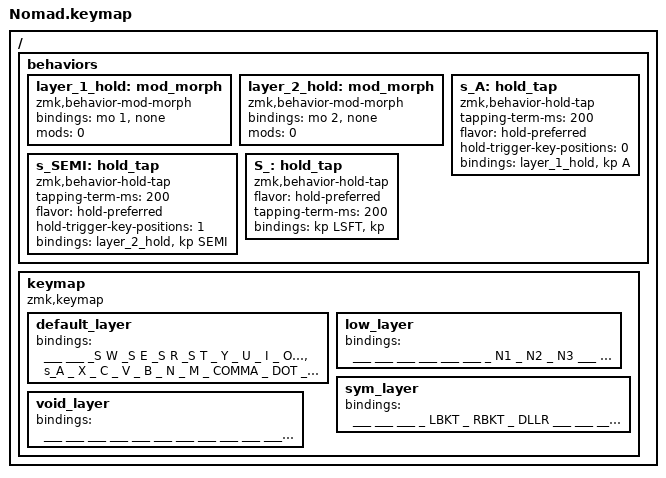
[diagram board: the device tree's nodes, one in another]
#include <behaviors.dtsi>
#include <dt-bindings/zmk/keys.h>
#include <dt-bindings/zmk/bt.h>

//custom includes
#include "include/positions.h"
#include "include/settings.dtsi"
#include "include/homerowmods.dtsi"

#define ___ &trans
#define _ &kp
#define _l &mo
#define _BOOT &bootloader
#define _CLR &bt BT_CLR
#define XXX &none

#define LOW 1
#define SYM 2

#define S_A &hm_shift_l LSHFT A
#define S_SEMI &hm_shift_r SEMI

/ {
  behaviors {
    layer_1_hold: mod_morph {
      compatible = "zmk,behavior-mod-morph";
      bindings = <&mo 1>, <&none>;
      mods = <0>;
    };

    layer_2_hold: mod_morph {
      compatible = "zmk,behavior-mod-morph";
      bindings = <&mo 2>, <&none>;
      mods = <0>;
    };

    s_A: hold_tap {
      compatible = "zmk,behavior-hold-tap";
      tapping-term-ms = <200>;
      flavor = "hold-preferred";
      hold-trigger-key-positions = <0>;
      bindings = <&layer_1_hold>, <&kp A>;
    };

    s_SEMI: hold_tap {
      compatible = "zmk,behavior-hold-tap";
      tapping-term-ms = <200>;
      flavor = "hold-preferred";
      hold-trigger-key-positions = <1>;
      bindings = <&layer_2_hold>, <&kp SEMI>;
    };
  };

  behaviors {
    S_: hold_tap {
      compatible = "zmk,behavior-hold-tap";
      #binding-cells = <1>;
      flavor = "hold-preferred";
      tapping-term-ms = <200>;
      bindings = <&kp LSFT>, <&kp>;
    };
  };

  keymap {
    compatible = "zmk,keymap";

    default_layer {
      bindings = <
        //                   ╭───────┬───────┬───────┬───────╮ ╭───────┬───────┬───────┬───────╮               
                ___     ___   _ W     _ E     _ R     _ T       _ Y     _ U     _ I     _ O       ___     ___  
        //   ╭───-───┬───-───┼───-───┼───-───┼───-───┼───-───┤ ├───-───┬───-───┼───-───┼───-───┼───-───┼───-───╮
              _ TAB   _ Q     _ S     _ D     _ F     _ G       _ H     _ J     _ K     _ L     _ P       ___  
        //   ├───-───┼───-───┼───-───┼───-───┼───-───┼───-───┤ ├───-───┼───-───┼───-───┼───-───┼───-───┼───-───┤
              _ CAPS  &s_A    _ X     _ C     _ V     _ B       _ N     _ M     _ COMMA _ DOT   _ SEMI  _ SQT  
        //   ├───-───┼───-───┼───-───┼───-───┼───-───┼───-───┤ ├───-───┼───-───┼───-───┼───-───┼───-───┼───-───┤
              _ LSHFT _ Z     _ LGUI  _l LOW  _ RET   _ SPACE   _ BSPC  _ RCTRL _l SYM  _ RALT  _ N8    _ RSHFT
        //   ╰───-───┴───-───┴───-───┴───-───┴───-───┴───-───╯ ╰───-───┴───-───┴───-───┴───-───┴───-───┴───-───╯
      >;
    };

    default_layer {
      bindings = <
        //                   ╭───────┬───────┬───────┬───────╮ ╭───────┬───────┬───────┬───────╮               
                ___     ___   _ W     _ E     _ R     _ T       _S Y    _S U    _S I    _S O      ___     ___  
        //   ╭───-───┬───-───┼───-───┼───-───┼───-───┼───-───┤ ├───-───┬───-───┼───-───┼───-───┼───-───┼───-───╮
              _ TAB   _ Q     _ S     _ D     _ F     _ G       _S H    _S J    _S K    _S L    _S P      ___  
        //   ├───-───┼───-───┼───-───┼───-───┼───-───┼───-───┤ ├───-───┼───-───┼───-───┼───-───┼───-───┼───-───┤
              _ CAPS  &s_A    _ X     _ C     _ V     _ B       _S N    _S M    _S COMMA _ DOT   _S SEMI _S SQT 
        //   ├───-───┼───-───┼───-───┼───-───┼───-───┼───-───┤ ├───-───┼───-───┼───-───┼───-───┼───-───┼───-───┤
              _ LSHFT _ Z     _ LGUI  _l LOW  _ RET   _ SPACE   _ BSPC  _ RCTRL _l SYM  _ RALT  _ N8    _ RSHFT
        //   ╰───-───┴───-───┴───-───┴───-───┴───-───┴───-───╯ ╰───-───┴───-───┴───-───┴───-───┴───-───┴───-───╯
      >;
    };

    default_layer {
      bindings = <
        //                   ╭───────┬───────┬───────┬───────╮ ╭───────┬───────┬───────┬───────╮               
                ___     ___   _S W    _S E    _S R    _S T      _ Y     _ U     _ I     _ O       ___     ___  
        //   ╭───-───┬───-───┼───-───┼───-───┼───-───┼───-───┤ ├───-───┬───-───┼───-───┼───-───┼───-───┼───-───╮
              _ TAB   _S Q    _S S    _S D    _S F    _S G      _ H     _ J     _ K     _ L     _ P       ___  
        //   ├───-───┼───-───┼───-───┼───-───┼───-───┼───-───┤ ├───-───┼───-───┼───-───┼───-───┼───-───┼───-───┤
              _ CAPS  &s_A    _ X     _ C     _ V     _ B       _ N     _ M     _ COMMA _ DOT   _ SEMI  _ SQT  
        //   ├───-───┼───-───┼───-───┼───-───┼───-───┼───-───┤ ├───-───┼───-───┼───-───┼───-───┼───-───┼───-───┤
              _ LSHFT _ Z     _ LGUI  _l LOW  _ RET   _ SPACE   _ BSPC  _ RCTRL _l SYM  _ RALT  _ N8    _ RSHFT
        //   ╰───-───┴───-───┴───-───┴───-───┴───-───┴───-───╯ ╰───-───┴───-───┴───-───┴───-───┴───-───┴───-───╯
      >;
    };

    low_layer {
      bindings = <
        //                   ╭───────┬───────┬───────┬───────╮ ╭───────┬───────┬───────┬───────╮                
                ___     ___     ___     ___     ___     ___     _ N1    _ N2    _ N3      ___     ___     ___   
        //   ╭───-───┬───-───┼───-───┼───-───┼───-───┼───-───┤ ├───-───┬───-───┼───-───┼───-───┼───-───┼───-───╮
                ___     ___     ___     ___     ___     ___     _ N4    _ N5    _ N6      ___     ___     ___   
        //   ├───-───┼───-───┼───-───┼───-───┼───-───┼───-───┤ ├───-───┼───-───┼───-───┼───-───┼───-───┼───-───┤
              _CLR      ___     ___     ___     ___     ___     _ N7    _ N8    _ N9      ___     ___     ___   
        //   ├───-───┼───-───┼───-───┼───-───┼───-───┼───-───┤ ├───-───┼───-───┼───-───┼───-───┼───-───┼───-───┤
              _BOOT     ___   _ LGUI    ___     ___     ___       ___     ___     ___     ___     ___    _BOOT  
        //   ╰───-───┴───-───┴───-───┴───-───┴───-───┴───-───╯ ╰───-───┴───-───┴───-───┴───-───┴───-───┴───-───╯
      >;
    };

    sym_layer {
      bindings = <
        //                   ╭───────┬───────┬───────┬───────╮ ╭───────┬───────┬───────┬───────╮                
                ___     ___     ___   _ LBKT  _ RBKT  _ DLLR      ___     ___     ___     ___     ___     ___   
        //   ╭───-───┬───-───┼───-───┼───-───┼───-───┼───-───┤ ├───-───┬───-───┼───-───┼───-───┼───-───┼───-───╮
                ___     ___     ___   _ LPAR  _ RPAR  _ AMPS    _ FSLH  _ BSLH    ___     ___     ___     ___   
        //   ├───-───┼───-───┼───-───┼───-───┼───-───┼───-───┤ ├───-───┼───-───┼───-───┼───-───┼───-───┼───-───┤
                ___     ___     ___   _ LCUR  _ RCUR  _ PIPE    _ QMARK _ EXCL    ___     ___     ___   _ TILD  
        //   ├───-───┼───-───┼───-───┼───-───┼───-───┼───-───┤ ├───-───┼───-───┼───-───┼───-───┼───-───┼───-───┤
                ___     ___     ___   _ LT    _ GT      ___     _ HASH  _ PRCT    ___     ___     ___     ___   
        //   ╰───-───┴───-───┴───-───┴───-───┴───-───┴───-───╯ ╰───-───┴───-───┴───-───┴───-───┴───-───┴───-───╯
      >;
    };

    void_layer {
      bindings = <
        //                   ╭───────┬───────┬───────┬───────╮ ╭───────┬───────┬───────┬───────╮                
                ___     ___     ___     ___     ___     ___       ___     ___     ___     ___     ___     ___   
        //   ╭───-───┬───-───┼───-───┼───-───┼───-───┼───-───┤ ├───-───┬───-───┼───-───┼───-───┼───-───┼───-───╮
                ___     ___     ___     ___     ___     ___       ___     ___     ___     ___     ___     ___   
        //   ├───-───┼───-───┼───-───┼───-───┼───-───┼───-───┤ ├───-───┼───-───┼───-───┼───-───┼───-───┼───-───┤
                ___     ___     ___     ___     ___     ___       ___     ___     ___     ___     ___     ___   
        //   ├───-───┼───-───┼───-───┼───-───┼───-───┼───-───┤ ├───-───┼───-───┼───-───┼───-───┼───-───┼───-───┤
                ___     ___     ___     ___     ___     ___       ___     ___     ___     ___     ___     ___   
        //   ╰───-───┴───-───┴───-───┴───-───┴───-───┴───-───╯ ╰───-───┴───-───┴───-───┴───-───┴───-───┴───-───╯
      >;
    };
  };
};
